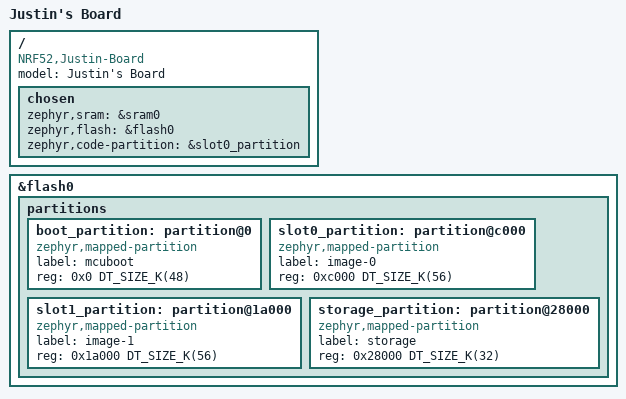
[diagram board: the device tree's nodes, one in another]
/dts-v1/;

#include <nordic/nrf52805_caaa.dtsi>
#include "Justin_Board-pinctrl.dtsi"

/ {
	model = "Justin's Board";
	compatible = "NRF52,Justin-Board";

	chosen {
		zephyr,sram = &sram0;
		zephyr,flash = &flash0;
		zephyr,code-partition = &slot0_partition;
	};
};

&flash0 {
	partitions {
		#address-cells = <1>;
		#size-cells = <1>;
		ranges;

		boot_partition: partition@0 {
			compatible = "zephyr,mapped-partition";
			label = "mcuboot";
			reg = <0x0 DT_SIZE_K(48)>;
		};

		slot0_partition: partition@c000 {
			compatible = "zephyr,mapped-partition";
			label = "image-0";
			reg = <0xc000 DT_SIZE_K(56)>;
		};

		slot1_partition: partition@1a000 {
			compatible = "zephyr,mapped-partition";
			label = "image-1";
			reg = <0x1a000 DT_SIZE_K(56)>;
		};

		storage_partition: partition@28000 {
			compatible = "zephyr,mapped-partition";
			label = "storage";
			reg = <0x28000 DT_SIZE_K(32)>;
		};
	};
};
